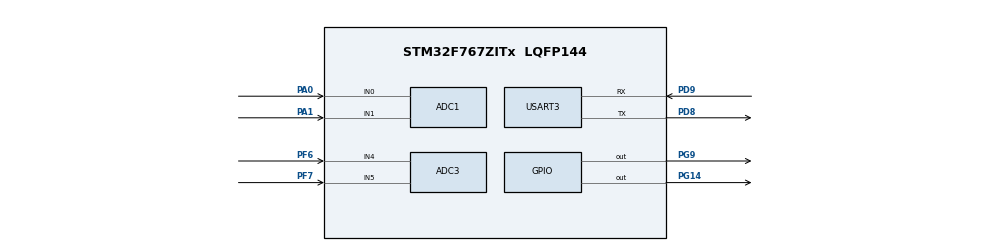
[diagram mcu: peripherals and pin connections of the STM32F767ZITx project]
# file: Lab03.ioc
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ADC1.Channel-0\#ChannelRegularConversion=ADC_CHANNEL_0
ADC1.NbrOfConversionFlag=1
ADC1.Rank-0\#ChannelRegularConversion=1
ADC1.SamplingTime-0\#ChannelRegularConversion=ADC_SAMPLETIME_3CYCLES
ADC1.master=1
ADC2.Channel-0\#ChannelRegularConversion=ADC_CHANNEL_0
ADC2.NbrOfConversionFlag=1
ADC2.Rank-0\#ChannelRegularConversion=1
ADC2.SamplingTime-0\#ChannelRegularConversion=ADC_SAMPLETIME_3CYCLES
ADC3.Channel-0\#ChannelRegularConversion=ADC_CHANNEL_4
ADC3.NbrOfConversionFlag=1
ADC3.Rank-0\#ChannelRegularConversion=1
ADC3.SamplingTime-0\#ChannelRegularConversion=ADC_SAMPLETIME_3CYCLES
CORTEX_M7.default_mode_Activation=1
Mcu.Family=STM32F7
Mcu.Name=STM32F767ZITx
Mcu.Package=LQFP144
NVIC.PriorityGroup=NVIC_PRIORITYGROUP_4
PA0/WKUP.Signal=ADCx_IN0
PA1.Signal=ADCx_IN1
PD8.Mode=Asynchronous
PD8.Signal=USART3_TX
PD9.Mode=Asynchronous
PD9.Signal=USART3_RX
PF6.Mode=IN4
PF6.Signal=ADC3_IN4
PF7.Mode=IN5
PF7.Signal=ADC3_IN5
PG14.Signal=GPIO_Output
PG9.Signal=GPIO_Output
ProjectManager.HeapSize=0x200
ProjectManager.StackSize=0x400
ProjectManager.TargetToolchain=STM32CubeIDE
RCC.HSE_VALUE=25000000
RCC.HSI_VALUE=16000000
RCC.LSE_VALUE=32768
RCC.USBFreq_Value=96000000
RCC.VCOOutputFreq_Value=192000000
SH.ADCx_IN0.0=ADC1_IN0,IN0
SH.ADCx_IN0.1=ADC2_IN0,IN0
SH.ADCx_IN0.2=ADC3_IN0,IN0
SH.ADCx_IN1.0=ADC1_IN1,IN1
SH.ADCx_IN1.1=ADC2_IN1,IN1
SH.ADCx_IN1.2=ADC3_IN1,IN1
USART3.VirtualMode-Asynchronous=VM_ASYNC
board=custom

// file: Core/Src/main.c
/* USER CODE BEGIN Header */
/**
  ******************************************************************************
  * @file           : main.c
  * @brief          : Main program body
  ******************************************************************************
  * @attention
  *
  * Copyright (c) 2024 STMicroelectronics.
  * All rights reserved.
  *
  * This software is licensed under terms that can be found in the LICENSE file
  * in the root directory of this software component.
  * If no LICENSE file comes with this software, it is provided AS-IS.
  *
  ******************************************************************************
  */
/* USER CODE END Header */
#include "main.h"
#include "adc.h"
#include "usart.h"
#include "gpio.h"

/* USER CODE BEGIN Includes */
#include "string.h"
#include "stdio.h"
/* USER CODE END Includes */

/* USER CODE BEGIN PV */
char inputChar;
char buffer[50];
uint8_t isRunning = 1;
uint8_t Firsttime = 1;
/* USER CODE END PV */

void SystemClock_Config(void);
static void MPU_Config(void);

int main(void)
{

  /* MPU Configuration--------------------------------------------------------*/
  MPU_Config();

  /* MCU Configuration--------------------------------------------------------*/

  /* Reset of all peripherals, Initializes the Flash interface and the Systick. */
  HAL_Init();

  /* Configure the system clock */
  SystemClock_Config();

  /* Initialize all configured peripherals */
  MX_GPIO_Init();
  MX_ADC1_Init();
  MX_ADC2_Init();
  MX_ADC3_Init();
  MX_USART3_UART_Init();
  /* USER CODE BEGIN 2 */
  char welcome[] = "Display Blinking LED PRESS (1, 2)\r\nDisplay Group Members PRESS m\r\nQuit PRESS q\r\n        Input => ";
  HAL_UART_Transmit(&huart3,(uint8_t*)welcome, strlen(welcome), HAL_MAX_DELAY);

  /* USER CODE END 2 */

  /* Infinite loop */
  while (1)
  {

////Example
//	  char ch1;
//	  while(__HAL_UART_GET_FLAG(&huart3,UART_FLAG_RXNE)== RESET){}
//	  HAL_UART_Receive(&huart3, (uint8_t*) &ch1, 1, 1000);
//	  HAL_UART_Transmit(&huart3, (uint8_t*) &ch1, 1, HAL_MAX_DELAY);

////01
//      char str[] = "Hello, World!!\r\n";
//      while(HAL_UART_GET_FLAG(&huart3,UART_FLAG_TC)==RESET){}
//      HAL_UART_Transmit(&huart3, (uint8_t*) str, strlen(str),1000);
//      HAL_Delay(500);

////02
//      char ch1 = 'A';
//      while(HAL_UART_GET_FLAG(&huart3,UART_FLAG_TC)==RESET){}
//      HAL_UART_Transmit(&huart3, (uint8_t)&ch1, 1, 1000);
//      HAL_Delay(500);

////03
//      HAL_UART_Receive(&huart3, (uint8_t)&inputChar, 1, HAL_MAX_DELAY);
//      if (inputChar == 'q') {
//            char quitMsg[] = "QUIT\r\n";
//            HAL_UART_Transmit(&huart3, (uint8_t)quitMsg, strlen(quitMsg), HAL_MAX_DELAY);
//            isRunning = 0;
//            break;
//      }
//      else {
//            snprintf(buffer, sizeof(buffer), "Input => %c\r\n", inputChar);
//            HAL_UART_Transmit(&huart3, (uint8_t)buffer, strlen(buffer), HAL_MAX_DELAY);
//          }

//04
	  HAL_UART_Receive(&huart3, (uint8_t*)&inputChar, 1, HAL_MAX_DELAY);
	       if (inputChar =='q'){
	       char quitMsg[] = "Quit\r\n";
	       HAL_UART_Transmit(&huart3,(uint8_t*)quitMsg, strlen(quitMsg), HAL_MAX_DELAY);
	       isRunning = 0;
	       break;
	       }
	       else {
	    if(Firsttime == 1){
	    	snprintf(buffer,sizeof(buffer), "%c\r\n" , inputChar);
	    	HAL_UART_Transmit(&huart3,(uint8_t*)buffer, strlen(buffer),HAL_MAX_DELAY);
	    	Firsttime = 0;
	    }
	    else if (Firsttime == 0){
	       snprintf(buffer,sizeof(buffer), "Input => %c\r\n" , inputChar);
	       HAL_UART_Transmit(&huart3,(uint8_t*)buffer, strlen(buffer),HAL_MAX_DELAY);
	    }
	       if (inputChar == '1') {
	       for (int i = 0; i < 3; i++) {
	      HAL_GPIO_WritePin(GPIOG, GPIO_PIN_9, GPIO_PIN_SET);
	      HAL_Delay(200);
	      HAL_GPIO_WritePin(GPIOG, GPIO_PIN_9, GPIO_PIN_RESET);
	      HAL_Delay(200);
	       }
	       } else if (inputChar == '2') {
	      for (int i = 0; i < 3; i++) {
	      HAL_GPIO_WritePin(GPIOG, GPIO_PIN_14, GPIO_PIN_SET);
	      HAL_Delay(200);
	      HAL_GPIO_WritePin(GPIOG, GPIO_PIN_14, GPIO_PIN_RESET);
	      HAL_Delay(200);
	       }
	       } else if (inputChar == 'm') {

	       char member1[] = "66015103\r\nNonthawat  Phongsrinual\r\n";
	       char member2[] = "66015152\r\nPasagon  Munesawat\r\n";

	       HAL_UART_Transmit(&huart3, (uint8_t*)member1, strlen(member1), HAL_MAX_DELAY);
	       HAL_UART_Transmit(&huart3, (uint8_t*)member2, strlen(member2), HAL_MAX_DELAY);

	       } else {
	      char invalidMsg[] = "Unknow Command\r\n";
	      HAL_UART_Transmit(&huart3, (uint8_t*)invalidMsg, strlen(invalidMsg), HAL_MAX_DELAY);
	       }
	       }

  }
}

void SystemClock_Config(void)
{
  RCC_OscInitTypeDef RCC_OscInitStruct = {0};
  RCC_ClkInitTypeDef RCC_ClkInitStruct = {0};

  /** Configure the main internal regulator output voltage
  */
  __HAL_RCC_PWR_CLK_ENABLE();
  __HAL_PWR_VOLTAGESCALING_CONFIG(PWR_REGULATOR_VOLTAGE_SCALE3);

  /** Initializes the RCC Oscillators according to the specified parameters
  * in the RCC_OscInitTypeDef structure.
  */
  RCC_OscInitStruct.OscillatorType = RCC_OSCILLATORTYPE_HSI;
  RCC_OscInitStruct.HSIState = RCC_HSI_ON;
  RCC_OscInitStruct.HSICalibrationValue = RCC_HSICALIBRATION_DEFAULT;
  RCC_OscInitStruct.PLL.PLLState = RCC_PLL_NONE;
  if (HAL_RCC_OscConfig(&RCC_OscInitStruct) != HAL_OK)
  {
    Error_Handler();
  }

  /** Initializes the CPU, AHB and APB buses clocks
  */
  RCC_ClkInitStruct.ClockType = RCC_CLOCKTYPE_HCLK|RCC_CLOCKTYPE_SYSCLK
                              |RCC_CLOCKTYPE_PCLK1|RCC_CLOCKTYPE_PCLK2;
  RCC_ClkInitStruct.SYSCLKSource = RCC_SYSCLKSOURCE_HSI;
  RCC_ClkInitStruct.AHBCLKDivider = RCC_SYSCLK_DIV1;
  RCC_ClkInitStruct.APB1CLKDivider = RCC_HCLK_DIV1;
  RCC_ClkInitStruct.APB2CLKDivider = RCC_HCLK_DIV1;

  if (HAL_RCC_ClockConfig(&RCC_ClkInitStruct, FLASH_LATENCY_0) != HAL_OK)
  {
    Error_Handler();
  }
}

 /* MPU Configuration */

void MPU_Config(void)
{
  MPU_Region_InitTypeDef MPU_InitStruct = {0};

  /* Disables the MPU */
  HAL_MPU_Disable();

  /** Initializes and configures the Region and the memory to be protected
  */
  MPU_InitStruct.Enable = MPU_REGION_ENABLE;
  MPU_InitStruct.Number = MPU_REGION_NUMBER0;
  MPU_InitStruct.BaseAddress = 0x0;
  MPU_InitStruct.Size = MPU_REGION_SIZE_4GB;
  MPU_InitStruct.SubRegionDisable = 0x87;
  MPU_InitStruct.TypeExtField = MPU_TEX_LEVEL0;
  MPU_InitStruct.AccessPermission = MPU_REGION_NO_ACCESS;
  MPU_InitStruct.DisableExec = MPU_INSTRUCTION_ACCESS_DISABLE;
  MPU_InitStruct.IsShareable = MPU_ACCESS_SHAREABLE;
  MPU_InitStruct.IsCacheable = MPU_ACCESS_NOT_CACHEABLE;
  MPU_InitStruct.IsBufferable = MPU_ACCESS_NOT_BUFFERABLE;

  HAL_MPU_ConfigRegion(&MPU_InitStruct);
  /* Enables the MPU */
  HAL_MPU_Enable(MPU_PRIVILEGED_DEFAULT);

}

void Error_Handler(void)
{
  __disable_irq();
  while (1)
  {
  }
}
